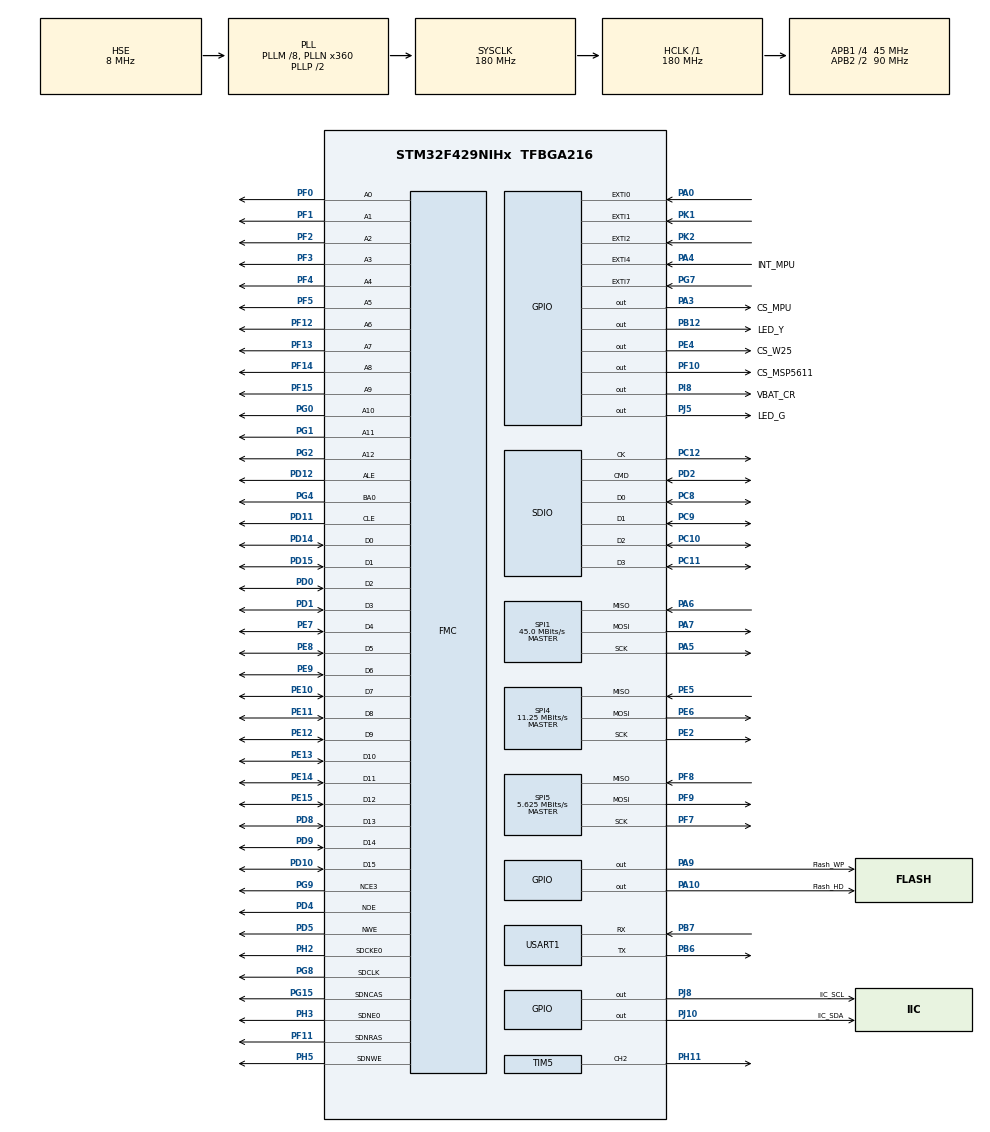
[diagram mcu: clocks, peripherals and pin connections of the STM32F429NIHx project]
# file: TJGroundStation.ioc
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ADC1.Channel-3\#ChannelRegularConversion=ADC_CHANNEL_TEMPSENSOR
ADC1.ContinuousConvMode=ENABLE
ADC1.DMAContinuousRequests=ENABLE
ADC1.NbrOfConversionFlag=1
ADC1.Rank-3\#ChannelRegularConversion=1
ADC1.SamplingTime-3\#ChannelRegularConversion=ADC_SAMPLETIME_3CYCLES
ADC1.ScanConvMode=ENABLE
ADC1.master=1
Dma.ADC1.0.Direction=DMA_PERIPH_TO_MEMORY
Dma.ADC1.0.FIFOMode=DMA_FIFOMODE_DISABLE
Dma.ADC1.0.Instance=DMA2_Stream0
Dma.ADC1.0.MemDataAlignment=DMA_MDATAALIGN_HALFWORD
Dma.ADC1.0.MemInc=DMA_MINC_ENABLE
Dma.ADC1.0.Mode=DMA_NORMAL
Dma.ADC1.0.PeriphDataAlignment=DMA_PDATAALIGN_HALFWORD
Dma.ADC1.0.PeriphInc=DMA_PINC_DISABLE
Dma.ADC1.0.Priority=DMA_PRIORITY_LOW
Dma.Request0=ADC1
Dma.Request1=USART1_RX
Dma.Request2=USART1_TX
Dma.USART1_RX.1.Direction=DMA_PERIPH_TO_MEMORY
Dma.USART1_RX.1.FIFOMode=DMA_FIFOMODE_DISABLE
Dma.USART1_RX.1.Instance=DMA2_Stream2
Dma.USART1_RX.1.MemDataAlignment=DMA_MDATAALIGN_BYTE
Dma.USART1_RX.1.MemInc=DMA_MINC_ENABLE
Dma.USART1_RX.1.Mode=DMA_NORMAL
Dma.USART1_RX.1.PeriphDataAlignment=DMA_PDATAALIGN_BYTE
Dma.USART1_RX.1.PeriphInc=DMA_PINC_DISABLE
Dma.USART1_RX.1.Priority=DMA_PRIORITY_LOW
Dma.USART1_TX.2.Direction=DMA_MEMORY_TO_PERIPH
Dma.USART1_TX.2.FIFOMode=DMA_FIFOMODE_DISABLE
Dma.USART1_TX.2.Instance=DMA2_Stream7
Dma.USART1_TX.2.MemDataAlignment=DMA_MDATAALIGN_BYTE
Dma.USART1_TX.2.MemInc=DMA_MINC_ENABLE
Dma.USART1_TX.2.Mode=DMA_NORMAL
Dma.USART1_TX.2.PeriphDataAlignment=DMA_PDATAALIGN_BYTE
Dma.USART1_TX.2.PeriphInc=DMA_PINC_DISABLE
Dma.USART1_TX.2.Priority=DMA_PRIORITY_LOW
FMC.AttributeSpaceHiZSetupTime1=3
FMC.AttributeSpaceHoldSetupTime1=1
FMC.AttributeSpaceSetupTime1=3
FMC.AttributeSpaceWaitSetupTime1=4
FMC.CASLatency1=FMC_SDRAM_CAS_LATENCY_1
FMC.ColumnBitsNumber1=FMC_SDRAM_COLUMN_BITS_NUM_8
FMC.CommonSpaceHiZSetupTime1=3
FMC.CommonSpaceHoldSetupTime1=1
FMC.CommonSpaceSetupTime1=3
FMC.CommonSpaceWaitSetupTime1=4
FMC.EccComputation1=FMC_NAND_ECC_DISABLE
FMC.ExitSelfRefreshDelay1=16
FMC.LoadToActiveDelay1=16
FMC.NandBlockNbr1=2076
FMC.NandBlockSize1=128
FMC.NandExtraCommandEnable1=DISABLE
FMC.NandPageSize1=8628
FMC.NandPlaneNbr1=1
FMC.NandPlaneSize1=1
FMC.NandSpareAreaSize1=436
FMC.RCDDelay1=16
FMC.RPDelay1=16
FMC.ReadBurst1=FMC_SDRAM_RBURST_ENABLE
FMC.ReadBurst2=FMC_SDRAM_RBURST_ENABLE
FMC.RowCycleDelay1=16
FMC.SelfRefreshTime1=16
FMC.TARSetupTime1=1
FMC.TCLRSetupTime1=1
FMC.WriteRecoveryTime1=16
Mcu.Family=STM32F4
Mcu.Name=STM32F429NIHx
Mcu.Package=TFBGA216
NVIC.DMA2_Stream0_IRQn=true\:0\:0\:false\:false\:true\:false\:true
NVIC.DMA2_Stream2_IRQn=true\:0\:0\:false\:false\:true\:false\:true
NVIC.DMA2_Stream7_IRQn=true\:0\:0\:false\:false\:true\:false\:true
NVIC.EXTI0_IRQn=true\:2\:2\:true\:false\:true\:true\:true
NVIC.EXTI1_IRQn=true\:2\:3\:true\:false\:true\:true\:true
NVIC.EXTI2_IRQn=true\:2\:3\:true\:false\:true\:true\:true
NVIC.EXTI4_IRQn=true\:1\:0\:true\:false\:true\:true\:true
NVIC.EXTI9_5_IRQn=true\:2\:0\:true\:false\:true\:true\:true
NVIC.PriorityGroup=NVIC_PRIORITYGROUP_2
NVIC.USART1_IRQn=true\:3\:3\:true\:false\:true\:true\:true
PA0/WKUP.Signal=GPXTI0
PA10.GPIO_Label=Flash_HD
PA10.Signal=GPIO_Output
PA13.Mode=Trace_Asynchronous_SW
PA13.Signal=SYS_JTMS-SWDIO
PA14.Mode=Trace_Asynchronous_SW
PA14.Signal=SYS_JTCK-SWCLK
PA3.GPIO_Label=CS_MPU
PA3.GPIO_Speed=GPIO_SPEED_FREQ_VERY_HIGH
PA3.PinState=GPIO_PIN_SET
PA3.Signal=GPIO_Output
PA4.GPIO_Label=INT_MPU
PA4.Signal=GPXTI4
PA5.Mode=Full_Duplex_Master
PA5.Signal=SPI1_SCK
PA6.Mode=Full_Duplex_Master
PA6.Signal=SPI1_MISO
PA7.Mode=Full_Duplex_Master
PA7.Signal=SPI1_MOSI
PA9.GPIO_Label=Flash_WP
PA9.Signal=GPIO_Output
PB12.GPIO_Label=LED_Y
PB12.GPIO_PuPd=GPIO_NOPULL
PB12.PinState=GPIO_PIN_SET
PB12.Signal=GPIO_Output
PB3.Mode=Trace_Asynchronous_SW
PB3.Signal=SYS_JTDO-SWO
PB6.Mode=Asynchronous
PB6.Signal=USART1_TX
PB7.Mode=Asynchronous
PB7.Signal=USART1_RX
PC10.Mode=SD_4_bits_Wide_bus
PC10.Signal=SDIO_D2
PC11.Mode=SD_4_bits_Wide_bus
PC11.Signal=SDIO_D3
PC12.Mode=SD_4_bits_Wide_bus
PC12.Signal=SDIO_CK
PC14/OSC32_IN.Mode=LSE-External-Oscillator
PC14/OSC32_IN.Signal=RCC_OSC32_IN
PC15/OSC32_OUT.Mode=LSE-External-Oscillator
PC15/OSC32_OUT.Signal=RCC_OSC32_OUT
PC8.Mode=SD_4_bits_Wide_bus
PC8.Signal=SDIO_D0
PC9.Mode=SD_4_bits_Wide_bus
PC9.Signal=SDIO_D1
PD0.Signal=FMC_D2_DA2
PD1.Signal=FMC_D3_DA3
PD10.Signal=FMC_D15_DA15
PD11.Signal=FMC_A16_CLE
PD12.Signal=FMC_A17_ALE
PD14.Signal=FMC_D0_DA0
PD15.Signal=FMC_D1_DA1
PD2.Mode=SD_4_bits_Wide_bus
PD2.Signal=SDIO_CMD
PD4.Signal=FMC_NOE
PD5.Signal=FMC_NWE
PD8.Signal=FMC_D13_DA13
PD9.Signal=FMC_D14_DA14
PE10.Signal=FMC_D7_DA7
PE11.Signal=FMC_D8_DA8
PE12.Signal=FMC_D9_DA9
PE13.Signal=FMC_D10_DA10
PE14.Signal=FMC_D11_DA11
PE15.Signal=FMC_D12_DA12
PE2.Mode=Full_Duplex_Master
PE2.Signal=SPI4_SCK
PE4.GPIO_Label=CS_W25
PE4.GPIO_Speed=GPIO_SPEED_FREQ_VERY_HIGH
PE4.PinState=GPIO_PIN_SET
PE4.Signal=GPIO_Output
PE5.Mode=Full_Duplex_Master
PE5.Signal=SPI4_MISO
PE6.Mode=Full_Duplex_Master
PE6.Signal=SPI4_MOSI
PE7.Signal=FMC_D4_DA4
PE8.Signal=FMC_D5_DA5
PE9.Signal=FMC_D6_DA6
PF0.Signal=FMC_A0
PF1.Signal=FMC_A1
PF10.GPIO_Label=CS_MSP5611
PF10.GPIO_PuPd=GPIO_PULLUP
PF10.PinState=GPIO_PIN_SET
PF10.Signal=GPIO_Output
PF11.Signal=FMC_SDNRAS
PF12.Signal=FMC_A6
PF13.Signal=FMC_A7
PF14.Signal=FMC_A8
PF15.Signal=FMC_A9
PF2.Signal=FMC_A2
PF3.Signal=FMC_A3
PF4.Signal=FMC_A4
PF5.Signal=FMC_A5
PF7.Mode=Full_Duplex_Master
PF7.Signal=SPI5_SCK
PF8.Mode=Full_Duplex_Master
PF8.Signal=SPI5_MISO
PF9.Mode=Full_Duplex_Master
PF9.Signal=SPI5_MOSI
PG0.Signal=FMC_A10
PG1.Signal=FMC_A11
PG15.Signal=FMC_SDNCAS
PG2.Signal=FMC_A12
PG4.Signal=FMC_A14_BA0
PG5.Signal=FMC_A15_BA1
PG7.GPIO_PuPd=GPIO_PULLUP
PG7.Signal=GPXTI7
PG8.Signal=FMC_SDCLK
PG9.Mode=NandChipSelect3_1
PG9.Signal=FMC_NCE3
PH0/OSC_IN.Mode=HSE-External-Oscillator
PH0/OSC_IN.Signal=RCC_OSC_IN
PH1/OSC_OUT.Mode=HSE-External-Oscillator
PH1/OSC_OUT.Signal=RCC_OSC_OUT
PH11.Signal=S_TIM5_CH2
PH2.Mode=SdramChipSelect1_1
PH2.Signal=FMC_SDCKE0
PH3.Mode=SdramChipSelect1_1
PH3.Signal=FMC_SDNE0
PH5.Signal=FMC_SDNWE
PI8.GPIO_Label=VBAT_CR
PI8.GPIO_PuPd=GPIO_PULLUP
PI8.PinState=GPIO_PIN_SET
PI8.Signal=GPIO_Output
PJ10.GPIO_Label=IIC_SDA
PJ10.GPIO_PuPd=GPIO_PULLUP
PJ10.GPIO_Speed=GPIO_SPEED_FREQ_VERY_HIGH
PJ10.Signal=GPIO_Output
PJ5.GPIO_Label=LED_G
PJ5.GPIO_PuPd=GPIO_PULLDOWN
PJ5.PinState=GPIO_PIN_SET
PJ5.Signal=GPIO_Output
PJ8.GPIO_Label=IIC_SCL
PJ8.GPIO_PuPd=GPIO_PULLUP
PJ8.GPIO_Speed=GPIO_SPEED_FREQ_VERY_HIGH
PJ8.Signal=GPIO_Output
PK1.GPIO_ModeDefaultEXTI=GPIO_MODE_IT_FALLING
PK1.Signal=GPXTI1
PK2.GPIO_ModeDefaultEXTI=GPIO_MODE_IT_FALLING
PK2.Signal=GPXTI2
ProjectManager.HeapSize=0x200
ProjectManager.StackSize=0x1000
ProjectManager.TargetToolchain=MDK-ARM V5
RCC.48MHZClocksFreq_Value=45000000
RCC.AHBFreq_Value=180000000
RCC.APB1CLKDivider=RCC_HCLK_DIV4
RCC.APB1Freq_Value=45000000
RCC.APB1TimFreq_Value=90000000
RCC.APB2CLKDivider=RCC_HCLK_DIV2
RCC.APB2Freq_Value=90000000
RCC.APB2TimFreq_Value=180000000
RCC.CortexFreq_Value=180000000
RCC.HCLKFreq_Value=180000000
RCC.HSE_VALUE=8000000
RCC.HSI_VALUE=16000000
RCC.PLLM=8
RCC.PLLN=360
RCC.PLLQ=8
RCC.PLLSourceVirtual=RCC_PLLSOURCE_HSE
RCC.RCC_RTC_Clock_Source=RCC_RTCCLKSOURCE_LSE
RCC.RCC_RTC_Clock_SourceVirtual=RCC_RTCCLKSOURCE_LSE
RCC.SYSCLKFreq_VALUE=180000000
RCC.SYSCLKSource=RCC_SYSCLKSOURCE_PLLCLK
RCC.VCOOutputFreq_Value=360000000
SH.FMC_A0.0=FMC_A0,13b-sda1
SH.FMC_A1.0=FMC_A1,13b-sda1
SH.FMC_A10.0=FMC_A10,13b-sda1
SH.FMC_A11.0=FMC_A11,13b-sda1
SH.FMC_A12.0=FMC_A12,13b-sda1
SH.FMC_A14_BA0.0=FMC_BA0,TwoSdramBanks1
SH.FMC_A15_BA1.0=FMC_BA1
SH.FMC_A16_CLE.0=FMC_CLE,8b-dmux1
SH.FMC_A17_ALE.0=FMC_ALE,8b-dmux1
SH.FMC_A2.0=FMC_A2,13b-sda1
SH.FMC_A3.0=FMC_A3,13b-sda1
SH.FMC_A4.0=FMC_A4,13b-sda1
SH.FMC_A5.0=FMC_A5,13b-sda1
SH.FMC_A6.0=FMC_A6,13b-sda1
SH.FMC_A7.0=FMC_A7,13b-sda1
SH.FMC_A8.0=FMC_A8,13b-sda1
SH.FMC_A9.0=FMC_A9,13b-sda1
SH.FMC_D0_DA0.0=FMC_D0,8b-dmux1
SH.FMC_D0_DA0.1=FMC_D0,sd-16b-d1
SH.FMC_D10_DA10.0=FMC_D10,sd-16b-d1
SH.FMC_D11_DA11.0=FMC_D11,sd-16b-d1
SH.FMC_D12_DA12.0=FMC_D12,sd-16b-d1
SH.FMC_D13_DA13.0=FMC_D13,sd-16b-d1
SH.FMC_D14_DA14.0=FMC_D14,sd-16b-d1
SH.FMC_D15_DA15.0=FMC_D15,sd-16b-d1
SH.FMC_D1_DA1.0=FMC_D1,8b-dmux1
SH.FMC_D1_DA1.1=FMC_D1,sd-16b-d1
SH.FMC_D2_DA2.0=FMC_D2,8b-dmux1
SH.FMC_D2_DA2.1=FMC_D2,sd-16b-d1
SH.FMC_D3_DA3.0=FMC_D3,8b-dmux1
SH.FMC_D3_DA3.1=FMC_D3,sd-16b-d1
SH.FMC_D4_DA4.0=FMC_D4,8b-dmux1
SH.FMC_D4_DA4.1=FMC_D4,sd-16b-d1
SH.FMC_D5_DA5.0=FMC_D5,8b-dmux1
SH.FMC_D5_DA5.1=FMC_D5,sd-16b-d1
SH.FMC_D6_DA6.0=FMC_D6,8b-dmux1
SH.FMC_D6_DA6.1=FMC_D6,sd-16b-d1
SH.FMC_D7_DA7.0=FMC_D7,8b-dmux1
SH.FMC_D7_DA7.1=FMC_D7,sd-16b-d1
SH.FMC_D8_DA8.0=FMC_D8,sd-16b-d1
SH.FMC_D9_DA9.0=FMC_D9,sd-16b-d1
SH.FMC_NOE.0=FMC_NOE,8b-dmux1
SH.FMC_NWE.0=FMC_NWE,8b-dmux1
SH.FMC_SDCLK.0=FMC_SDCLK,13b-sda1
SH.FMC_SDNCAS.0=FMC_SDNCAS,13b-sda1
SH.FMC_SDNRAS.0=FMC_SDNRAS,13b-sda1
SH.FMC_SDNWE.0=FMC_SDNWE,13b-sda1
SH.S_TIM5_CH2.0=TIM5_CH2,PWM Generation2 CH2
SPI1.BaudRatePrescaler=SPI_BAUDRATEPRESCALER_2
SPI1.CLKPhase=SPI_PHASE_2EDGE
SPI1.CLKPolarity=SPI_POLARITY_HIGH
SPI1.CalculateBaudRate=45.0 MBits/s
SPI1.Direction=SPI_DIRECTION_2LINES
SPI1.Mode=SPI_MODE_MASTER
SPI1.VirtualType=VM_MASTER
SPI4.BaudRatePrescaler=SPI_BAUDRATEPRESCALER_8
SPI4.CLKPhase=SPI_PHASE_2EDGE
SPI4.CLKPolarity=SPI_POLARITY_HIGH
SPI4.CRCCalculation=SPI_CRCCALCULATION_DISABLE
SPI4.CalculateBaudRate=11.25 MBits/s
SPI4.Direction=SPI_DIRECTION_2LINES
SPI4.Mode=SPI_MODE_MASTER
SPI4.VirtualType=VM_MASTER
SPI5.BaudRatePrescaler=SPI_BAUDRATEPRESCALER_16
SPI5.CalculateBaudRate=5.625 MBits/s
SPI5.Direction=SPI_DIRECTION_2LINES
SPI5.Mode=SPI_MODE_MASTER
SPI5.VirtualType=VM_MASTER
TIM5.AutoReloadPreload=TIM_AUTORELOAD_PRELOAD_DISABLE
TIM5.Channel-PWM\ Generation2\ CH2=TIM_CHANNEL_2
TIM5.Period=4999
TIM5.Prescaler=8999
TIM5.Pulse-PWM\ Generation2\ CH2=100
USART1.VirtualMode=VM_ASYNC
VP_ADC1_TempSens_Input.Mode=IN-TempSens
VP_FATFS_VS_Generic.Mode=User_defined
VP_TIM5_VS_ClockSourceINT.Mode=Internal
board=custom

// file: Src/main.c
/* USER CODE BEGIN Header */
/**
  ******************************************************************************
  * @file           : main.c
  * @brief          : Main program body
  ******************************************************************************
  * @attention
  *
  * <h2><center>&copy; Copyright (c) 2020 STMicroelectronics.
  * All rights reserved.</center></h2>
  *
  * This software component is licensed by ST under BSD 3-Clause license,
  * the "License"; You may not use this file except in compliance with the
  * License. You may obtain a copy of the License at:
  *                        opensource.org/licenses/BSD-3-Clause
  *
  ******************************************************************************
  */
/* USER CODE END Header */

#include "main.h"
#include "fatfs.h"

/* USER CODE BEGIN Includes */
#include "console.h"
#include "stm32f4xx_hal_uart.h"
#include "MS.h"
#include "W25.h"
#include "LTC2944.h"
#include "RTC.h"
#include "MPU.h"
#include "LTC2944.h"
#include "NAND.h"
#include "SRAM.h"
/* USER CODE END Includes */

ADC_HandleTypeDef hadc1;
DMA_HandleTypeDef hdma_adc1;

SD_HandleTypeDef hsd;

SPI_HandleTypeDef hspi1;
SPI_HandleTypeDef hspi4;
SPI_HandleTypeDef hspi5;

TIM_HandleTypeDef htim5;

UART_HandleTypeDef huart1;
DMA_HandleTypeDef hdma_usart1_rx;
DMA_HandleTypeDef hdma_usart1_tx;

NAND_HandleTypeDef hnand1;
SDRAM_HandleTypeDef hsdram1;

/* USER CODE BEGIN PV */
extern uint32_t ADC_TMP[64];
extern uint8_t RX_BUFF[128];
extern uint8_t TX_BUFF[128];
/* USER CODE END PV */

void SystemClock_Config(void);
static void MX_GPIO_Init(void);
static void MX_DMA_Init(void);
static void MX_TIM5_Init(void);
static void MX_USART1_UART_Init(void);
static void MX_SPI4_Init(void);
static void MX_SPI5_Init(void);
static void MX_ADC1_Init(void);
static void MX_FMC_Init(void);
static void MX_SPI1_Init(void);
static void MX_SDIO_SD_Init(void);

int main(void)
{

  /* MCU Configuration--------------------------------------------------------*/

  /* Reset of all peripherals, Initializes the Flash interface and the Systick. */
  HAL_Init();

  /* Configure the system clock */
  SystemClock_Config();

  /* Initialize all configured peripherals */
  MX_GPIO_Init();
  MX_DMA_Init();
  MX_TIM5_Init();
  MX_USART1_UART_Init();
  MX_SPI4_Init();
  MX_SPI5_Init();
  MX_ADC1_Init();
  MX_FATFS_Init();
  MX_FMC_Init();
  MX_SPI1_Init();
  MX_SDIO_SD_Init();
  /* USER CODE BEGIN 2 */
	HAL_ADC_Start_DMA(&hadc1,(uint32_t*)ADC_TMP,16);
	HAL_TIM_PWM_Start(&htim5,TIM_CHANNEL_2);
	HAL_UART_Receive_DMA(&huart1,RX_BUFF,128);
	__HAL_UART_ENABLE_IT(&huart1,UART_IT_IDLE);
	__HAL_DMA_ENABLE_IT(&hdma_usart1_tx,DMA_IT_TC);

	SPI1->CR1 |= 0x00000040; //enable spi1 MPU9250
	SPI4->CR1 |= 0x00000040; //enable spi4 W25M02
	SPI5->CR1 |= 0x00000040; //enable spi5 MS5611
	FMC_Bank2_3->PCR3 &= 0xfffffffd; //disable PWAITEN

	MS_Init();
	W25_Init();
	RTC_Init();
	IMU_Init();
	ltc2944_init();
	NAND_RST();
	SRAM_Init();
	LED_G = 0;

	console_log();

  /* USER CODE END 2 */

  /* Infinite loop */
  /* USER CODE BEGIN WHILE */
  while (1)
  {
		console_exe();

    /* USER CODE END WHILE */

  }
}

void SystemClock_Config(void)
{
  RCC_OscInitTypeDef RCC_OscInitStruct = {0};
  RCC_ClkInitTypeDef RCC_ClkInitStruct = {0};

  /** Configure the main internal regulator output voltage
  */
  __HAL_RCC_PWR_CLK_ENABLE();
  __HAL_PWR_VOLTAGESCALING_CONFIG(PWR_REGULATOR_VOLTAGE_SCALE1);
  /** Initializes the CPU, AHB and APB busses clocks
  */
  RCC_OscInitStruct.OscillatorType = RCC_OSCILLATORTYPE_HSE;
  RCC_OscInitStruct.HSEState = RCC_HSE_ON;
  RCC_OscInitStruct.PLL.PLLState = RCC_PLL_ON;
  RCC_OscInitStruct.PLL.PLLSource = RCC_PLLSOURCE_HSE;
  RCC_OscInitStruct.PLL.PLLM = 8;
  RCC_OscInitStruct.PLL.PLLN = 360;
  RCC_OscInitStruct.PLL.PLLP = RCC_PLLP_DIV2;
  RCC_OscInitStruct.PLL.PLLQ = 8;
  if (HAL_RCC_OscConfig(&RCC_OscInitStruct) != HAL_OK)
  {
    Error_Handler();
  }
  /** Activate the Over-Drive mode
  */
  if (HAL_PWREx_EnableOverDrive() != HAL_OK)
  {
    Error_Handler();
  }
  /** Initializes the CPU, AHB and APB busses clocks
  */
  RCC_ClkInitStruct.ClockType = RCC_CLOCKTYPE_HCLK|RCC_CLOCKTYPE_SYSCLK
                              |RCC_CLOCKTYPE_PCLK1|RCC_CLOCKTYPE_PCLK2;
  RCC_ClkInitStruct.SYSCLKSource = RCC_SYSCLKSOURCE_PLLCLK;
  RCC_ClkInitStruct.AHBCLKDivider = RCC_SYSCLK_DIV1;
  RCC_ClkInitStruct.APB1CLKDivider = RCC_HCLK_DIV4;
  RCC_ClkInitStruct.APB2CLKDivider = RCC_HCLK_DIV2;

  if (HAL_RCC_ClockConfig(&RCC_ClkInitStruct, FLASH_LATENCY_5) != HAL_OK)
  {
    Error_Handler();
  }
}

static void MX_ADC1_Init(void)
{

  ADC_ChannelConfTypeDef sConfig = {0};

  /** Configure the global features of the ADC (Clock, Resolution, Data Alignment and number of conversion)
  */
  hadc1.Instance = ADC1;
  hadc1.Init.ClockPrescaler = ADC_CLOCK_SYNC_PCLK_DIV4;
  hadc1.Init.Resolution = ADC_RESOLUTION_12B;
  hadc1.Init.ScanConvMode = ENABLE;
  hadc1.Init.ContinuousConvMode = ENABLE;
  hadc1.Init.DiscontinuousConvMode = DISABLE;
  hadc1.Init.ExternalTrigConvEdge = ADC_EXTERNALTRIGCONVEDGE_NONE;
  hadc1.Init.ExternalTrigConv = ADC_SOFTWARE_START;
  hadc1.Init.DataAlign = ADC_DATAALIGN_RIGHT;
  hadc1.Init.NbrOfConversion = 1;
  hadc1.Init.DMAContinuousRequests = ENABLE;
  hadc1.Init.EOCSelection = ADC_EOC_SINGLE_CONV;
  if (HAL_ADC_Init(&hadc1) != HAL_OK)
  {
    Error_Handler();
  }
  /** Configure for the selected ADC regular channel its corresponding rank in the sequencer and its sample time.
  */
  sConfig.Channel = ADC_CHANNEL_TEMPSENSOR;
  sConfig.Rank = 1;
  sConfig.SamplingTime = ADC_SAMPLETIME_3CYCLES;
  if (HAL_ADC_ConfigChannel(&hadc1, &sConfig) != HAL_OK)
  {
    Error_Handler();
  }

}

static void MX_SDIO_SD_Init(void)
{

  hsd.Instance = SDIO;
  hsd.Init.ClockEdge = SDIO_CLOCK_EDGE_RISING;
  hsd.Init.ClockBypass = SDIO_CLOCK_BYPASS_DISABLE;
  hsd.Init.ClockPowerSave = SDIO_CLOCK_POWER_SAVE_DISABLE;
  hsd.Init.BusWide = SDIO_BUS_WIDE_1B;
  hsd.Init.HardwareFlowControl = SDIO_HARDWARE_FLOW_CONTROL_DISABLE;
  hsd.Init.ClockDiv = 0;
  if (HAL_SD_Init(&hsd) != HAL_OK)
  {
    Error_Handler();
  }
  if (HAL_SD_ConfigWideBusOperation(&hsd, SDIO_BUS_WIDE_4B) != HAL_OK)
  {
    Error_Handler();
  }

}

static void MX_SPI1_Init(void)
{

  /* SPI1 parameter configuration*/
  hspi1.Instance = SPI1;
  hspi1.Init.Mode = SPI_MODE_MASTER;
  hspi1.Init.Direction = SPI_DIRECTION_2LINES;
  hspi1.Init.DataSize = SPI_DATASIZE_8BIT;
  hspi1.Init.CLKPolarity = SPI_POLARITY_HIGH;
  hspi1.Init.CLKPhase = SPI_PHASE_2EDGE;
  hspi1.Init.NSS = SPI_NSS_SOFT;
  hspi1.Init.BaudRatePrescaler = SPI_BAUDRATEPRESCALER_2;
  hspi1.Init.FirstBit = SPI_FIRSTBIT_MSB;
  hspi1.Init.TIMode = SPI_TIMODE_DISABLE;
  hspi1.Init.CRCCalculation = SPI_CRCCALCULATION_DISABLE;
  hspi1.Init.CRCPolynomial = 10;
  if (HAL_SPI_Init(&hspi1) != HAL_OK)
  {
    Error_Handler();
  }

}

static void MX_SPI4_Init(void)
{

  /* SPI4 parameter configuration*/
  hspi4.Instance = SPI4;
  hspi4.Init.Mode = SPI_MODE_MASTER;
  hspi4.Init.Direction = SPI_DIRECTION_2LINES;
  hspi4.Init.DataSize = SPI_DATASIZE_8BIT;
  hspi4.Init.CLKPolarity = SPI_POLARITY_HIGH;
  hspi4.Init.CLKPhase = SPI_PHASE_2EDGE;
  hspi4.Init.NSS = SPI_NSS_SOFT;
  hspi4.Init.BaudRatePrescaler = SPI_BAUDRATEPRESCALER_8;
  hspi4.Init.FirstBit = SPI_FIRSTBIT_MSB;
  hspi4.Init.TIMode = SPI_TIMODE_DISABLE;
  hspi4.Init.CRCCalculation = SPI_CRCCALCULATION_DISABLE;
  hspi4.Init.CRCPolynomial = 10;
  if (HAL_SPI_Init(&hspi4) != HAL_OK)
  {
    Error_Handler();
  }

}

static void MX_SPI5_Init(void)
{

  /* SPI5 parameter configuration*/
  hspi5.Instance = SPI5;
  hspi5.Init.Mode = SPI_MODE_MASTER;
  hspi5.Init.Direction = SPI_DIRECTION_2LINES;
  hspi5.Init.DataSize = SPI_DATASIZE_8BIT;
  hspi5.Init.CLKPolarity = SPI_POLARITY_LOW;
  hspi5.Init.CLKPhase = SPI_PHASE_1EDGE;
  hspi5.Init.NSS = SPI_NSS_SOFT;
  hspi5.Init.BaudRatePrescaler = SPI_BAUDRATEPRESCALER_16;
  hspi5.Init.FirstBit = SPI_FIRSTBIT_MSB;
  hspi5.Init.TIMode = SPI_TIMODE_DISABLE;
  hspi5.Init.CRCCalculation = SPI_CRCCALCULATION_DISABLE;
  hspi5.Init.CRCPolynomial = 10;
  if (HAL_SPI_Init(&hspi5) != HAL_OK)
  {
    Error_Handler();
  }

}

static void MX_TIM5_Init(void)
{

  TIM_ClockConfigTypeDef sClockSourceConfig = {0};
  TIM_MasterConfigTypeDef sMasterConfig = {0};
  TIM_OC_InitTypeDef sConfigOC = {0};

  htim5.Instance = TIM5;
  htim5.Init.Prescaler = 8999;
  htim5.Init.CounterMode = TIM_COUNTERMODE_UP;
  htim5.Init.Period = 4999;
  htim5.Init.ClockDivision = TIM_CLOCKDIVISION_DIV1;
  htim5.Init.AutoReloadPreload = TIM_AUTORELOAD_PRELOAD_DISABLE;
  if (HAL_TIM_Base_Init(&htim5) != HAL_OK)
  {
    Error_Handler();
  }
  sClockSourceConfig.ClockSource = TIM_CLOCKSOURCE_INTERNAL;
  if (HAL_TIM_ConfigClockSource(&htim5, &sClockSourceConfig) != HAL_OK)
  {
    Error_Handler();
  }
  if (HAL_TIM_PWM_Init(&htim5) != HAL_OK)
  {
    Error_Handler();
  }
  sMasterConfig.MasterOutputTrigger = TIM_TRGO_RESET;
  sMasterConfig.MasterSlaveMode = TIM_MASTERSLAVEMODE_DISABLE;
  if (HAL_TIMEx_MasterConfigSynchronization(&htim5, &sMasterConfig) != HAL_OK)
  {
    Error_Handler();
  }
  sConfigOC.OCMode = TIM_OCMODE_PWM1;
  sConfigOC.Pulse = 100;
  sConfigOC.OCPolarity = TIM_OCPOLARITY_HIGH;
  sConfigOC.OCFastMode = TIM_OCFAST_DISABLE;
  if (HAL_TIM_PWM_ConfigChannel(&htim5, &sConfigOC, TIM_CHANNEL_2) != HAL_OK)
  {
    Error_Handler();
  }
  HAL_TIM_MspPostInit(&htim5);

}

static void MX_USART1_UART_Init(void)
{

  huart1.Instance = USART1;
  huart1.Init.BaudRate = 115200;
  huart1.Init.WordLength = UART_WORDLENGTH_8B;
  huart1.Init.StopBits = UART_STOPBITS_1;
  huart1.Init.Parity = UART_PARITY_NONE;
  huart1.Init.Mode = UART_MODE_TX_RX;
  huart1.Init.HwFlowCtl = UART_HWCONTROL_NONE;
  huart1.Init.OverSampling = UART_OVERSAMPLING_16;
  if (HAL_UART_Init(&huart1) != HAL_OK)
  {
    Error_Handler();
  }

}

static void MX_DMA_Init(void)
{

  /* DMA controller clock enable */
  __HAL_RCC_DMA2_CLK_ENABLE();

  /* DMA interrupt init */
  /* DMA2_Stream0_IRQn interrupt configuration */
  HAL_NVIC_SetPriority(DMA2_Stream0_IRQn, 0, 0);
  HAL_NVIC_EnableIRQ(DMA2_Stream0_IRQn);
  /* DMA2_Stream2_IRQn interrupt configuration */
  HAL_NVIC_SetPriority(DMA2_Stream2_IRQn, 0, 0);
  HAL_NVIC_EnableIRQ(DMA2_Stream2_IRQn);
  /* DMA2_Stream7_IRQn interrupt configuration */
  HAL_NVIC_SetPriority(DMA2_Stream7_IRQn, 0, 0);
  HAL_NVIC_EnableIRQ(DMA2_Stream7_IRQn);

}

/* FMC initialization function */
static void MX_FMC_Init(void)
{

  FMC_NAND_PCC_TimingTypeDef ComSpaceTiming = {0};
  FMC_NAND_PCC_TimingTypeDef AttSpaceTiming = {0};
  FMC_SDRAM_TimingTypeDef SdramTiming = {0};

  /** Perform the NAND1 memory initialization sequence
  */
  hnand1.Instance = FMC_NAND_DEVICE;
  /* hnand1.Init */
  hnand1.Init.NandBank = FMC_NAND_BANK3;
  hnand1.Init.Waitfeature = FMC_NAND_PCC_WAIT_FEATURE_DISABLE;
  hnand1.Init.MemoryDataWidth = FMC_NAND_PCC_MEM_BUS_WIDTH_8;
  hnand1.Init.EccComputation = FMC_NAND_ECC_DISABLE;
  hnand1.Init.ECCPageSize = FMC_NAND_ECC_PAGE_SIZE_256BYTE;
  hnand1.Init.TCLRSetupTime = 1;
  hnand1.Init.TARSetupTime = 1;
  /* hnand1.Config */
  hnand1.Config.PageSize = 8628;
  hnand1.Config.SpareAreaSize = 436;
  hnand1.Config.BlockSize = 128;
  hnand1.Config.BlockNbr = 2076;
  hnand1.Config.PlaneNbr = 1;
  hnand1.Config.PlaneSize = 1;
  hnand1.Config.ExtraCommandEnable = DISABLE;
  /* ComSpaceTiming */
  ComSpaceTiming.SetupTime = 3;
  ComSpaceTiming.WaitSetupTime = 4;
  ComSpaceTiming.HoldSetupTime = 1;
  ComSpaceTiming.HiZSetupTime = 3;
  /* AttSpaceTiming */
  AttSpaceTiming.SetupTime = 3;
  AttSpaceTiming.WaitSetupTime = 4;
  AttSpaceTiming.HoldSetupTime = 1;
  AttSpaceTiming.HiZSetupTime = 3;

  if (HAL_NAND_Init(&hnand1, &ComSpaceTiming, &AttSpaceTiming) != HAL_OK)
  {
    Error_Handler( );
  }

  /** Perform the SDRAM1 memory initialization sequence
  */
  hsdram1.Instance = FMC_SDRAM_DEVICE;
  /* hsdram1.Init */
  hsdram1.Init.SDBank = FMC_SDRAM_BANK1;
  hsdram1.Init.ColumnBitsNumber = FMC_SDRAM_COLUMN_BITS_NUM_8;
  hsdram1.Init.RowBitsNumber = FMC_SDRAM_ROW_BITS_NUM_13;
  hsdram1.Init.MemoryDataWidth = FMC_SDRAM_MEM_BUS_WIDTH_16;
  hsdram1.Init.InternalBankNumber = FMC_SDRAM_INTERN_BANKS_NUM_2;
  hsdram1.Init.CASLatency = FMC_SDRAM_CAS_LATENCY_1;
  hsdram1.Init.WriteProtection = FMC_SDRAM_WRITE_PROTECTION_DISABLE;
  hsdram1.Init.SDClockPeriod = FMC_SDRAM_CLOCK_DISABLE;
  hsdram1.Init.ReadBurst = FMC_SDRAM_RBURST_ENABLE;
  hsdram1.Init.ReadPipeDelay = FMC_SDRAM_RPIPE_DELAY_0;
  /* SdramTiming */
  SdramTiming.LoadToActiveDelay = 16;
  SdramTiming.ExitSelfRefreshDelay = 16;
  SdramTiming.SelfRefreshTime = 16;
  SdramTiming.RowCycleDelay = 16;
  SdramTiming.WriteRecoveryTime = 16;
  SdramTiming.RPDelay = 16;
  SdramTiming.RCDDelay = 16;

  if (HAL_SDRAM_Init(&hsdram1, &SdramTiming) != HAL_OK)
  {
    Error_Handler( );
  }

}

static void MX_GPIO_Init(void)
{
  GPIO_InitTypeDef GPIO_InitStruct = {0};

  /* GPIO Ports Clock Enable */
  __HAL_RCC_GPIOE_CLK_ENABLE();
  __HAL_RCC_GPIOB_CLK_ENABLE();
  __HAL_RCC_GPIOC_CLK_ENABLE();
  __HAL_RCC_GPIOA_CLK_ENABLE();
  __HAL_RCC_GPIOG_CLK_ENABLE();
  __HAL_RCC_GPIOD_CLK_ENABLE();
  __HAL_RCC_GPIOI_CLK_ENABLE();
  __HAL_RCC_GPIOF_CLK_ENABLE();
  __HAL_RCC_GPIOK_CLK_ENABLE();
  __HAL_RCC_GPIOH_CLK_ENABLE();
  __HAL_RCC_GPIOJ_CLK_ENABLE();

  /*Configure GPIO pin Output Level */
  HAL_GPIO_WritePin(CS_W25_GPIO_Port, CS_W25_Pin, GPIO_PIN_SET);

  /*Configure GPIO pin Output Level */
  HAL_GPIO_WritePin(VBAT_CR_GPIO_Port, VBAT_CR_Pin, GPIO_PIN_SET);

  /*Configure GPIO pin Output Level */
  HAL_GPIO_WritePin(GPIOA, Flash_HD_Pin|Flash_WP_Pin, GPIO_PIN_RESET);

  /*Configure GPIO pin Output Level */
  HAL_GPIO_WritePin(GPIOJ, IIC_SCL_Pin|IIC_SDA_Pin, GPIO_PIN_RESET);

  /*Configure GPIO pin Output Level */
  HAL_GPIO_WritePin(CS_MSP5611_GPIO_Port, CS_MSP5611_Pin, GPIO_PIN_SET);

  /*Configure GPIO pin Output Level */
  HAL_GPIO_WritePin(LED_Y_GPIO_Port, LED_Y_Pin, GPIO_PIN_SET);

  /*Configure GPIO pin Output Level */
  HAL_GPIO_WritePin(LED_G_GPIO_Port, LED_G_Pin, GPIO_PIN_SET);

  /*Configure GPIO pin Output Level */
  HAL_GPIO_WritePin(CS_MPU_GPIO_Port, CS_MPU_Pin, GPIO_PIN_SET);

  /*Configure GPIO pin : CS_W25_Pin */
  GPIO_InitStruct.Pin = CS_W25_Pin;
  GPIO_InitStruct.Mode = GPIO_MODE_OUTPUT_PP;
  GPIO_InitStruct.Pull = GPIO_NOPULL;
  GPIO_InitStruct.Speed = GPIO_SPEED_FREQ_VERY_HIGH;
  HAL_GPIO_Init(CS_W25_GPIO_Port, &GPIO_InitStruct);

  /*Configure GPIO pin : VBAT_CR_Pin */
  GPIO_InitStruct.Pin = VBAT_CR_Pin;
  GPIO_InitStruct.Mode = GPIO_MODE_OUTPUT_PP;
  GPIO_InitStruct.Pull = GPIO_PULLUP;
  GPIO_InitStruct.Speed = GPIO_SPEED_FREQ_LOW;
  HAL_GPIO_Init(VBAT_CR_GPIO_Port, &GPIO_InitStruct);

  /*Configure GPIO pins : Flash_HD_Pin Flash_WP_Pin */
  GPIO_InitStruct.Pin = Flash_HD_Pin|Flash_WP_Pin;
  GPIO_InitStruct.Mode = GPIO_MODE_OUTPUT_PP;
  GPIO_InitStruct.Pull = GPIO_NOPULL;
  GPIO_InitStruct.Speed = GPIO_SPEED_FREQ_LOW;
  HAL_GPIO_Init(GPIOA, &GPIO_InitStruct);

  /*Configure GPIO pins : PK1 PK2 */
  GPIO_InitStruct.Pin = GPIO_PIN_1|GPIO_PIN_2;
  GPIO_InitStruct.Mode = GPIO_MODE_IT_FALLING;
  GPIO_InitStruct.Pull = GPIO_NOPULL;
  HAL_GPIO_Init(GPIOK, &GPIO_InitStruct);

  /*Configure GPIO pins : IIC_SCL_Pin IIC_SDA_Pin */
  GPIO_InitStruct.Pin = IIC_SCL_Pin|IIC_SDA_Pin;
  GPIO_InitStruct.Mode = GPIO_MODE_OUTPUT_PP;
  GPIO_InitStruct.Pull = GPIO_PULLUP;
  GPIO_InitStruct.Speed = GPIO_SPEED_FREQ_VERY_HIGH;
  HAL_GPIO_Init(GPIOJ, &GPIO_InitStruct);

  /*Configure GPIO pin : PG7 */
  GPIO_InitStruct.Pin = GPIO_PIN_7;
  GPIO_InitStruct.Mode = GPIO_MODE_IT_RISING;
  GPIO_InitStruct.Pull = GPIO_PULLUP;
  HAL_GPIO_Init(GPIOG, &GPIO_InitStruct);

  /*Configure GPIO pin : CS_MSP5611_Pin */
  GPIO_InitStruct.Pin = CS_MSP5611_Pin;
  GPIO_InitStruct.Mode = GPIO_MODE_OUTPUT_PP;
  GPIO_InitStruct.Pull = GPIO_PULLUP;
  GPIO_InitStruct.Speed = GPIO_SPEED_FREQ_LOW;
  HAL_GPIO_Init(CS_MSP5611_GPIO_Port, &GPIO_InitStruct);

  /*Configure GPIO pin : LED_Y_Pin */
  GPIO_InitStruct.Pin = LED_Y_Pin;
  GPIO_InitStruct.Mode = GPIO_MODE_OUTPUT_PP;
  GPIO_InitStruct.Pull = GPIO_NOPULL;
  GPIO_InitStruct.Speed = GPIO_SPEED_FREQ_LOW;
  HAL_GPIO_Init(LED_Y_GPIO_Port, &GPIO_InitStruct);

  /*Configure GPIO pin : LED_G_Pin */
  GPIO_InitStruct.Pin = LED_G_Pin;
  GPIO_InitStruct.Mode = GPIO_MODE_OUTPUT_PP;
  GPIO_InitStruct.Pull = GPIO_PULLDOWN;
  GPIO_InitStruct.Speed = GPIO_SPEED_FREQ_LOW;
  HAL_GPIO_Init(LED_G_GPIO_Port, &GPIO_InitStruct);

  /*Configure GPIO pins : PA0 INT_MPU_Pin */
  GPIO_InitStruct.Pin = GPIO_PIN_0|INT_MPU_Pin;
  GPIO_InitStruct.Mode = GPIO_MODE_IT_RISING;
  GPIO_InitStruct.Pull = GPIO_NOPULL;
  HAL_GPIO_Init(GPIOA, &GPIO_InitStruct);

  /*Configure GPIO pin : CS_MPU_Pin */
  GPIO_InitStruct.Pin = CS_MPU_Pin;
  GPIO_InitStruct.Mode = GPIO_MODE_OUTPUT_PP;
  GPIO_InitStruct.Pull = GPIO_NOPULL;
  GPIO_InitStruct.Speed = GPIO_SPEED_FREQ_VERY_HIGH;
  HAL_GPIO_Init(CS_MPU_GPIO_Port, &GPIO_InitStruct);

  /* EXTI interrupt init*/
  HAL_NVIC_SetPriority(EXTI0_IRQn, 2, 2);
  HAL_NVIC_EnableIRQ(EXTI0_IRQn);

  HAL_NVIC_SetPriority(EXTI1_IRQn, 2, 3);
  HAL_NVIC_EnableIRQ(EXTI1_IRQn);

  HAL_NVIC_SetPriority(EXTI2_IRQn, 2, 3);
  HAL_NVIC_EnableIRQ(EXTI2_IRQn);

  HAL_NVIC_SetPriority(EXTI4_IRQn, 1, 0);
  HAL_NVIC_EnableIRQ(EXTI4_IRQn);

  HAL_NVIC_SetPriority(EXTI9_5_IRQn, 2, 0);
  HAL_NVIC_EnableIRQ(EXTI9_5_IRQn);

}

void Error_Handler(void)
{
  /* USER CODE BEGIN Error_Handler_Debug */
  /* User can add his own implementation to report the HAL error return state */
	LED_G = 1;
	printf("[ERR HANDLER]\r\n");

  /* USER CODE END Error_Handler_Debug */
}

/************************ (C) COPYRIGHT STMicroelectronics *****END OF FILE****/
